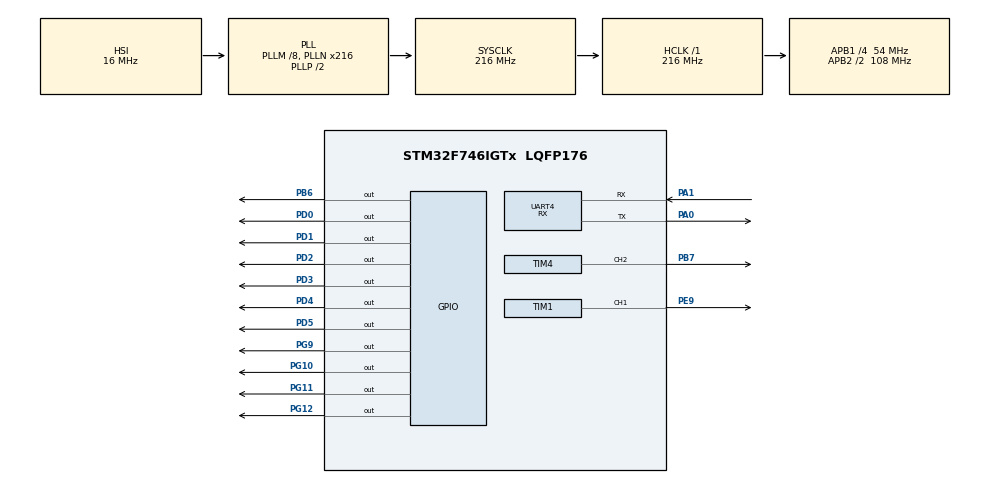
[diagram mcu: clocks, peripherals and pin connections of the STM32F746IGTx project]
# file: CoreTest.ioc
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CORTEX_M7.ART_ACCLERATOR_ENABLE=0
CORTEX_M7.CPU_DCache=Enabled
CORTEX_M7.CPU_ICache=Enabled
CORTEX_M7.PREFETCH_ENABLE=0
Dma.Request0=TIM1_CH1
Dma.TIM1_CH1.0.Direction=DMA_MEMORY_TO_PERIPH
Dma.TIM1_CH1.0.FIFOMode=DMA_FIFOMODE_DISABLE
Dma.TIM1_CH1.0.Instance=DMA2_Stream1
Dma.TIM1_CH1.0.MemDataAlignment=DMA_MDATAALIGN_BYTE
Dma.TIM1_CH1.0.MemInc=DMA_MINC_ENABLE
Dma.TIM1_CH1.0.Mode=DMA_NORMAL
Dma.TIM1_CH1.0.PeriphDataAlignment=DMA_PDATAALIGN_BYTE
Dma.TIM1_CH1.0.PeriphInc=DMA_PINC_DISABLE
Dma.TIM1_CH1.0.Priority=DMA_PRIORITY_MEDIUM
FREERTOS.HEAP_NUMBER=3
FREERTOS.Tasks01=defaultTask,24,1280,StartDefaultTask,Default,NULL,Dynamic,NULL,NULL
FREERTOS.configENABLE_FPU=1
FREERTOS.configUSE_NEWLIB_REENTRANT=1
FREERTOS.copyHeapFile=0
Mcu.Family=STM32F7
Mcu.Name=STM32F746IGTx
Mcu.Package=LQFP176
NVIC.DMA2_Stream1_IRQn=true\:5\:0\:false\:false\:false\:true\:false\:false
NVIC.PriorityGroup=NVIC_PRIORITYGROUP_4
NVIC.TIM1_UP_TIM10_IRQn=true\:0\:0\:false\:false\:true\:false\:false\:true
NVIC.TIM4_IRQn=true\:5\:0\:false\:false\:true\:true\:true\:true
NVIC.TimeBase=TIM1_UP_TIM10_IRQn
NVIC.TimeBaseIP=TIM10
NVIC.UART4_IRQn=true\:10\:0\:true\:false\:false\:true\:true\:false
PA0/WKUP.Mode=Asynchronous
PA0/WKUP.Signal=UART4_TX
PA1.Mode=Asynchronous
PA1.Signal=UART4_RX
PA13.Mode=Trace_Asynchronous_SW
PA13.Signal=SYS_JTMS-SWDIO
PA14.Mode=Trace_Asynchronous_SW
PA14.Signal=SYS_JTCK-SWCLK
PB3.Mode=Trace_Asynchronous_SW
PB3.Signal=SYS_JTDO-SWO
PB6.Signal=GPIO_Output
PB7.Signal=S_TIM4_CH2
PD0.GPIO_Speed=GPIO_SPEED_FREQ_HIGH
PD0.Signal=GPIO_Output
PD1.GPIO_Speed=GPIO_SPEED_FREQ_HIGH
PD1.Signal=GPIO_Output
PD2.GPIO_Speed=GPIO_SPEED_FREQ_HIGH
PD2.Signal=GPIO_Output
PD3.GPIO_Speed=GPIO_SPEED_FREQ_HIGH
PD3.Signal=GPIO_Output
PD4.GPIO_Speed=GPIO_SPEED_FREQ_HIGH
PD4.Signal=GPIO_Output
PD5.GPIO_Speed=GPIO_SPEED_FREQ_HIGH
PD5.Signal=GPIO_Output
PE9.Signal=S_TIM1_CH1
PG10.Signal=GPIO_Output
PG11.Signal=GPIO_Output
PG12.Signal=GPIO_Output
PG9.Signal=GPIO_Output
ProjectManager.HeapSize=0x200
ProjectManager.StackSize=0x400
ProjectManager.TargetToolchain=STM32CubeIDE
RCC.AHBFreq_Value=216000000
RCC.APB1CLKDivider=RCC_HCLK_DIV4
RCC.APB1Freq_Value=54000000
RCC.APB1TimFreq_Value=108000000
RCC.APB2CLKDivider=RCC_HCLK_DIV2
RCC.APB2Freq_Value=108000000
RCC.APB2TimFreq_Value=216000000
RCC.CortexFreq_Value=216000000
RCC.HCLKFreq_Value=216000000
RCC.HSE_VALUE=25000000
RCC.HSI_VALUE=16000000
RCC.LSE_VALUE=32768
RCC.PLLM=8
RCC.PLLN=216
RCC.SYSCLKFreq_VALUE=216000000
RCC.SYSCLKSource=RCC_SYSCLKSOURCE_PLLCLK
RCC.USBFreq_Value=216000000
RCC.VCOOutputFreq_Value=432000000
SH.S_TIM1_CH1.0=TIM1_CH1,PWM Generation1 CH1
SH.S_TIM4_CH2.0=TIM4_CH2,PWM Generation2 CH2
TIM1.Channel-PWM\ Generation1\ CH1=TIM_CHANNEL_1
TIM1.CounterMode=TIM_COUNTERMODE_DOWN
TIM1.OCFastMode_PWM-PWM\ Generation1\ CH1=TIM_OCFAST_ENABLE
TIM1.OCIdleState_1=TIM_OCIDLESTATE_SET
TIM1.OCPolarity_1=TIM_OCPOLARITY_LOW
TIM1.Period=200
TIM1.Prescaler=0
TIM1.Pulse-PWM\ Generation1\ CH1=100
TIM1.RepetitionCounter=0
TIM4.Channel-PWM\ Generation2\ CH2=TIM_CHANNEL_2
TIM4.CounterMode=TIM_COUNTERMODE_DOWN
TIM4.OCFastMode_PWM-PWM\ Generation2\ CH2=TIM_OCFAST_ENABLE
TIM4.OCPolarity_2=TIM_OCPOLARITY_LOW
TIM4.Period=7000
TIM4.Prescaler=0
TIM4.Pulse-PWM\ Generation2\ CH2=6000
UART4.Mode=MODE_RX
VP_FREERTOS_VS_CMSIS_V2.Mode=CMSIS_V2
VP_SYS_VS_tim10.Mode=TIM10
VP_TIM1_VS_ClockSourceINT.Mode=Internal
VP_TIM1_VS_OPM.Mode=OPM_bit
VP_TIM4_VS_ClockSourceINT.Mode=Internal
board=custom

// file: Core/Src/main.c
/* USER CODE BEGIN Header */
/**
  ******************************************************************************
  * @file           : main.c
  * @brief          : Main program body
  ******************************************************************************
  * @attention
  *
  * <h2><center>&copy; Copyright (c) 2020 STMicroelectronics.
  * All rights reserved.</center></h2>
  *
  * This software component is licensed by ST under Ultimate Liberty license
  * SLA0044, the "License"; You may not use this file except in compliance with
  * the License. You may obtain a copy of the License at:
  *                             www.st.com/SLA0044
  *
  ******************************************************************************
  */
/* USER CODE END Header */

#include "main.h"
#include "cmsis_os.h"

TIM_HandleTypeDef htim1;
TIM_HandleTypeDef htim4;
DMA_HandleTypeDef hdma_tim1_ch1;

UART_HandleTypeDef huart4;

/* Definitions for defaultTask */
osThreadId_t defaultTaskHandle;
const osThreadAttr_t defaultTask_attributes = {
  .name = "defaultTask",
  .priority = (osPriority_t) osPriorityNormal,
  .stack_size = 1280 * 4
};
/* USER CODE BEGIN PV */
void matrix_task();
/* USER CODE END PV */

void SystemClock_Config(void);
static void MX_GPIO_Init(void);
static void MX_DMA_Init(void);
static void MX_TIM4_Init(void);
static void MX_TIM1_Init(void);
static void MX_UART4_Init(void);
void StartDefaultTask(void *argument);

int main(void)
{
  /* USER CODE BEGIN 1 */
	__HAL_DBGMCU_FREEZE_TIM10();
	__HAL_DBGMCU_FREEZE_TIM1();
	__HAL_DBGMCU_FREEZE_TIM4();
  /* USER CODE END 1 */

  /* Enable I-Cache---------------------------------------------------------*/
  SCB_EnableICache();

  /* Enable D-Cache---------------------------------------------------------*/
  SCB_EnableDCache();

  /* MCU Configuration--------------------------------------------------------*/

  /* Reset of all peripherals, Initializes the Flash interface and the Systick. */
  HAL_Init();

  /* Configure the system clock */
  SystemClock_Config();

  /* Initialize all configured peripherals */
  MX_GPIO_Init();
  MX_DMA_Init();
  MX_TIM4_Init();
  MX_TIM1_Init();
  MX_UART4_Init();

  /* Init scheduler */
  osKernelInitialize();

  /* Create the thread(s) */
  /* creation of defaultTask */
  defaultTaskHandle = osThreadNew(StartDefaultTask, NULL, &defaultTask_attributes);

  /* Start scheduler */
  osKernelStart();

  /* We should never get here as control is now taken by the scheduler */
  /* Infinite loop */
  while (1)
  {

  }
}

void SystemClock_Config(void)
{
  RCC_OscInitTypeDef RCC_OscInitStruct = {0};
  RCC_ClkInitTypeDef RCC_ClkInitStruct = {0};
  RCC_PeriphCLKInitTypeDef PeriphClkInitStruct = {0};

  /** Configure the main internal regulator output voltage
  */
  __HAL_RCC_PWR_CLK_ENABLE();
  __HAL_PWR_VOLTAGESCALING_CONFIG(PWR_REGULATOR_VOLTAGE_SCALE1);
  /** Initializes the CPU, AHB and APB busses clocks
  */
  RCC_OscInitStruct.OscillatorType = RCC_OSCILLATORTYPE_HSI;
  RCC_OscInitStruct.HSIState = RCC_HSI_ON;
  RCC_OscInitStruct.HSICalibrationValue = RCC_HSICALIBRATION_DEFAULT;
  RCC_OscInitStruct.PLL.PLLState = RCC_PLL_ON;
  RCC_OscInitStruct.PLL.PLLSource = RCC_PLLSOURCE_HSI;
  RCC_OscInitStruct.PLL.PLLM = 8;
  RCC_OscInitStruct.PLL.PLLN = 216;
  RCC_OscInitStruct.PLL.PLLP = RCC_PLLP_DIV2;
  RCC_OscInitStruct.PLL.PLLQ = 2;
  if (HAL_RCC_OscConfig(&RCC_OscInitStruct) != HAL_OK)
  {
    Error_Handler();
  }
  /** Activate the Over-Drive mode
  */
  if (HAL_PWREx_EnableOverDrive() != HAL_OK)
  {
    Error_Handler();
  }
  /** Initializes the CPU, AHB and APB busses clocks
  */
  RCC_ClkInitStruct.ClockType = RCC_CLOCKTYPE_HCLK|RCC_CLOCKTYPE_SYSCLK
                              |RCC_CLOCKTYPE_PCLK1|RCC_CLOCKTYPE_PCLK2;
  RCC_ClkInitStruct.SYSCLKSource = RCC_SYSCLKSOURCE_PLLCLK;
  RCC_ClkInitStruct.AHBCLKDivider = RCC_SYSCLK_DIV1;
  RCC_ClkInitStruct.APB1CLKDivider = RCC_HCLK_DIV4;
  RCC_ClkInitStruct.APB2CLKDivider = RCC_HCLK_DIV2;

  if (HAL_RCC_ClockConfig(&RCC_ClkInitStruct, FLASH_LATENCY_7) != HAL_OK)
  {
    Error_Handler();
  }
  PeriphClkInitStruct.PeriphClockSelection = RCC_PERIPHCLK_UART4;
  PeriphClkInitStruct.Uart4ClockSelection = RCC_UART4CLKSOURCE_PCLK1;
  if (HAL_RCCEx_PeriphCLKConfig(&PeriphClkInitStruct) != HAL_OK)
  {
    Error_Handler();
  }
}

static void MX_TIM1_Init(void)
{

  TIM_ClockConfigTypeDef sClockSourceConfig = {0};
  TIM_MasterConfigTypeDef sMasterConfig = {0};
  TIM_OC_InitTypeDef sConfigOC = {0};
  TIM_BreakDeadTimeConfigTypeDef sBreakDeadTimeConfig = {0};

  htim1.Instance = TIM1;
  htim1.Init.Prescaler = 0;
  htim1.Init.CounterMode = TIM_COUNTERMODE_DOWN;
  htim1.Init.Period = 200;
  htim1.Init.ClockDivision = TIM_CLOCKDIVISION_DIV1;
  htim1.Init.RepetitionCounter = 0;
  htim1.Init.AutoReloadPreload = TIM_AUTORELOAD_PRELOAD_DISABLE;
  if (HAL_TIM_Base_Init(&htim1) != HAL_OK)
  {
    Error_Handler();
  }
  sClockSourceConfig.ClockSource = TIM_CLOCKSOURCE_INTERNAL;
  if (HAL_TIM_ConfigClockSource(&htim1, &sClockSourceConfig) != HAL_OK)
  {
    Error_Handler();
  }
  if (HAL_TIM_PWM_Init(&htim1) != HAL_OK)
  {
    Error_Handler();
  }
  if (HAL_TIM_OnePulse_Init(&htim1, TIM_OPMODE_SINGLE) != HAL_OK)
  {
    Error_Handler();
  }
  sMasterConfig.MasterOutputTrigger = TIM_TRGO_RESET;
  sMasterConfig.MasterOutputTrigger2 = TIM_TRGO2_RESET;
  sMasterConfig.MasterSlaveMode = TIM_MASTERSLAVEMODE_DISABLE;
  if (HAL_TIMEx_MasterConfigSynchronization(&htim1, &sMasterConfig) != HAL_OK)
  {
    Error_Handler();
  }
  sConfigOC.OCMode = TIM_OCMODE_PWM1;
  sConfigOC.Pulse = 100;
  sConfigOC.OCPolarity = TIM_OCPOLARITY_LOW;
  sConfigOC.OCNPolarity = TIM_OCNPOLARITY_HIGH;
  sConfigOC.OCFastMode = TIM_OCFAST_ENABLE;
  sConfigOC.OCIdleState = TIM_OCIDLESTATE_SET;
  sConfigOC.OCNIdleState = TIM_OCNIDLESTATE_RESET;
  if (HAL_TIM_PWM_ConfigChannel(&htim1, &sConfigOC, TIM_CHANNEL_1) != HAL_OK)
  {
    Error_Handler();
  }
  sBreakDeadTimeConfig.OffStateRunMode = TIM_OSSR_DISABLE;
  sBreakDeadTimeConfig.OffStateIDLEMode = TIM_OSSI_DISABLE;
  sBreakDeadTimeConfig.LockLevel = TIM_LOCKLEVEL_OFF;
  sBreakDeadTimeConfig.DeadTime = 0;
  sBreakDeadTimeConfig.BreakState = TIM_BREAK_DISABLE;
  sBreakDeadTimeConfig.BreakPolarity = TIM_BREAKPOLARITY_HIGH;
  sBreakDeadTimeConfig.BreakFilter = 0;
  sBreakDeadTimeConfig.Break2State = TIM_BREAK2_DISABLE;
  sBreakDeadTimeConfig.Break2Polarity = TIM_BREAK2POLARITY_HIGH;
  sBreakDeadTimeConfig.Break2Filter = 0;
  sBreakDeadTimeConfig.AutomaticOutput = TIM_AUTOMATICOUTPUT_DISABLE;
  if (HAL_TIMEx_ConfigBreakDeadTime(&htim1, &sBreakDeadTimeConfig) != HAL_OK)
  {
    Error_Handler();
  }
  HAL_TIM_MspPostInit(&htim1);

}

static void MX_TIM4_Init(void)
{

  TIM_ClockConfigTypeDef sClockSourceConfig = {0};
  TIM_MasterConfigTypeDef sMasterConfig = {0};
  TIM_OC_InitTypeDef sConfigOC = {0};

  htim4.Instance = TIM4;
  htim4.Init.Prescaler = 0;
  htim4.Init.CounterMode = TIM_COUNTERMODE_DOWN;
  htim4.Init.Period = 7000;
  htim4.Init.ClockDivision = TIM_CLOCKDIVISION_DIV1;
  htim4.Init.AutoReloadPreload = TIM_AUTORELOAD_PRELOAD_DISABLE;
  if (HAL_TIM_Base_Init(&htim4) != HAL_OK)
  {
    Error_Handler();
  }
  sClockSourceConfig.ClockSource = TIM_CLOCKSOURCE_INTERNAL;
  if (HAL_TIM_ConfigClockSource(&htim4, &sClockSourceConfig) != HAL_OK)
  {
    Error_Handler();
  }
  if (HAL_TIM_PWM_Init(&htim4) != HAL_OK)
  {
    Error_Handler();
  }
  sMasterConfig.MasterOutputTrigger = TIM_TRGO_RESET;
  sMasterConfig.MasterSlaveMode = TIM_MASTERSLAVEMODE_DISABLE;
  if (HAL_TIMEx_MasterConfigSynchronization(&htim4, &sMasterConfig) != HAL_OK)
  {
    Error_Handler();
  }
  sConfigOC.OCMode = TIM_OCMODE_PWM1;
  sConfigOC.Pulse = 6000;
  sConfigOC.OCPolarity = TIM_OCPOLARITY_LOW;
  sConfigOC.OCFastMode = TIM_OCFAST_ENABLE;
  if (HAL_TIM_PWM_ConfigChannel(&htim4, &sConfigOC, TIM_CHANNEL_2) != HAL_OK)
  {
    Error_Handler();
  }
  /* USER CODE BEGIN TIM4_Init 2 */
  HAL_TIM_PWM_Start(&htim4, TIM_CHANNEL_2);
  /* USER CODE END TIM4_Init 2 */
  HAL_TIM_MspPostInit(&htim4);

}

static void MX_UART4_Init(void)
{

  huart4.Instance = UART4;
  huart4.Init.BaudRate = 115200;
  huart4.Init.WordLength = UART_WORDLENGTH_8B;
  huart4.Init.StopBits = UART_STOPBITS_1;
  huart4.Init.Parity = UART_PARITY_NONE;
  huart4.Init.Mode = UART_MODE_RX;
  huart4.Init.HwFlowCtl = UART_HWCONTROL_NONE;
  huart4.Init.OverSampling = UART_OVERSAMPLING_16;
  huart4.Init.OneBitSampling = UART_ONE_BIT_SAMPLE_DISABLE;
  huart4.AdvancedInit.AdvFeatureInit = UART_ADVFEATURE_NO_INIT;
  if (HAL_UART_Init(&huart4) != HAL_OK)
  {
    Error_Handler();
  }

}

static void MX_DMA_Init(void)
{

  /* DMA controller clock enable */
  __HAL_RCC_DMA2_CLK_ENABLE();

  /* DMA interrupt init */
  /* DMA2_Stream1_IRQn interrupt configuration */
  HAL_NVIC_SetPriority(DMA2_Stream1_IRQn, 5, 0);
  HAL_NVIC_EnableIRQ(DMA2_Stream1_IRQn);

}

static void MX_GPIO_Init(void)
{
  GPIO_InitTypeDef GPIO_InitStruct = {0};

  /* GPIO Ports Clock Enable */
  __HAL_RCC_GPIOA_CLK_ENABLE();
  __HAL_RCC_GPIOE_CLK_ENABLE();
  __HAL_RCC_GPIOD_CLK_ENABLE();
  __HAL_RCC_GPIOG_CLK_ENABLE();
  __HAL_RCC_GPIOB_CLK_ENABLE();

  /*Configure GPIO pin Output Level */
  HAL_GPIO_WritePin(GPIOD, GPIO_PIN_0|GPIO_PIN_1|GPIO_PIN_2|GPIO_PIN_3
                          |GPIO_PIN_4|GPIO_PIN_5, GPIO_PIN_RESET);

  /*Configure GPIO pin Output Level */
  HAL_GPIO_WritePin(GPIOG, GPIO_PIN_9|GPIO_PIN_10|GPIO_PIN_11|GPIO_PIN_12, GPIO_PIN_RESET);

  /*Configure GPIO pin Output Level */
  HAL_GPIO_WritePin(GPIOB, GPIO_PIN_6, GPIO_PIN_RESET);

  /*Configure GPIO pins : PD0 PD1 PD2 PD3
                           PD4 PD5 */
  GPIO_InitStruct.Pin = GPIO_PIN_0|GPIO_PIN_1|GPIO_PIN_2|GPIO_PIN_3
                          |GPIO_PIN_4|GPIO_PIN_5;
  GPIO_InitStruct.Mode = GPIO_MODE_OUTPUT_PP;
  GPIO_InitStruct.Pull = GPIO_NOPULL;
  GPIO_InitStruct.Speed = GPIO_SPEED_FREQ_HIGH;
  HAL_GPIO_Init(GPIOD, &GPIO_InitStruct);

  /*Configure GPIO pins : PG9 PG10 PG11 PG12 */
  GPIO_InitStruct.Pin = GPIO_PIN_9|GPIO_PIN_10|GPIO_PIN_11|GPIO_PIN_12;
  GPIO_InitStruct.Mode = GPIO_MODE_OUTPUT_PP;
  GPIO_InitStruct.Pull = GPIO_NOPULL;
  GPIO_InitStruct.Speed = GPIO_SPEED_FREQ_LOW;
  HAL_GPIO_Init(GPIOG, &GPIO_InitStruct);

  /*Configure GPIO pin : PB6 */
  GPIO_InitStruct.Pin = GPIO_PIN_6;
  GPIO_InitStruct.Mode = GPIO_MODE_OUTPUT_PP;
  GPIO_InitStruct.Pull = GPIO_NOPULL;
  GPIO_InitStruct.Speed = GPIO_SPEED_FREQ_LOW;
  HAL_GPIO_Init(GPIOB, &GPIO_InitStruct);

}

void StartDefaultTask(void *argument)
{
  /* USER CODE BEGIN 5 */
  /* Infinite loop */
	matrix_task();
  /* USER CODE END 5 */
}

 /**
  * @brief  Period elapsed callback in non blocking mode
  * @note   This function is called  when TIM10 interrupt took place, inside
  * HAL_TIM_IRQHandler(). It makes a direct call to HAL_IncTick() to increment
  * a global variable "uwTick" used as application time base.
  * @param  htim : TIM handle
  * @retval None
  */
void HAL_TIM_PeriodElapsedCallback(TIM_HandleTypeDef *htim)
{
  if (htim->Instance == TIM10) {
    HAL_IncTick();
  }
}

void Error_Handler(void)
{
}

/************************ (C) COPYRIGHT STMicroelectronics *****END OF FILE****/
